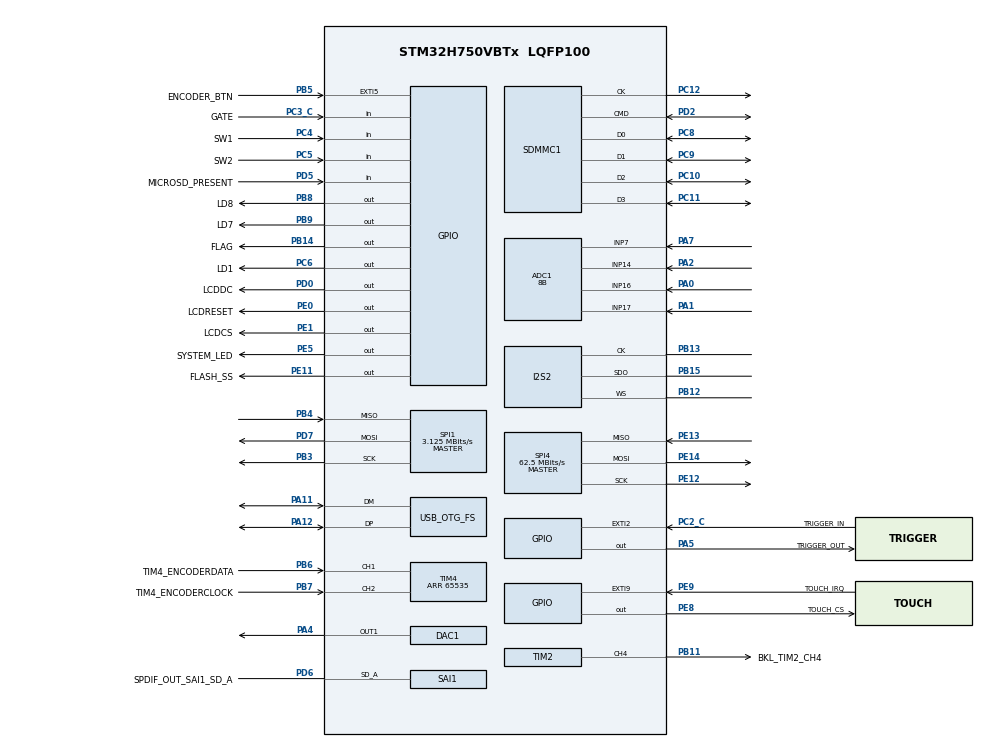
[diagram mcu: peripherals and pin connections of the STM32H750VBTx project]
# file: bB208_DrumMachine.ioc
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ADC1.Channel-0\#ChannelRegularConversion=ADC_CHANNEL_16
ADC1.Channel-1\#ChannelRegularConversion=ADC_CHANNEL_17
ADC1.Channel-2\#ChannelRegularConversion=ADC_CHANNEL_14
ADC1.Channel-3\#ChannelRegularConversion=ADC_CHANNEL_7
ADC1.ConversionDataManagement=ADC_CONVERSIONDATA_DMA_CIRCULAR
ADC1.EOCSelection=ADC_EOC_SEQ_CONV
ADC1.ExternalTrigConv=ADC_EXTERNALTRIG_T15_TRGO
ADC1.NbrOfConversion=4
ADC1.NbrOfConversionFlag=1
ADC1.OffsetNumber-0\#ChannelRegularConversion=ADC_OFFSET_NONE
ADC1.OffsetNumber-1\#ChannelRegularConversion=ADC_OFFSET_NONE
ADC1.OffsetNumber-2\#ChannelRegularConversion=ADC_OFFSET_NONE
ADC1.OffsetNumber-3\#ChannelRegularConversion=ADC_OFFSET_NONE
ADC1.OffsetSignedSaturation-0\#ChannelRegularConversion=DISABLE
ADC1.OffsetSignedSaturation-1\#ChannelRegularConversion=DISABLE
ADC1.OffsetSignedSaturation-2\#ChannelRegularConversion=DISABLE
ADC1.OffsetSignedSaturation-3\#ChannelRegularConversion=DISABLE
ADC1.OversamplingMode=ENABLE
ADC1.Rank-0\#ChannelRegularConversion=1
ADC1.Rank-1\#ChannelRegularConversion=2
ADC1.Rank-2\#ChannelRegularConversion=3
ADC1.Rank-3\#ChannelRegularConversion=4
ADC1.Ratio=8
ADC1.Resolution=ADC_RESOLUTION_8B
ADC1.RightBitShift=ADC_RIGHTBITSHIFT_3
ADC1.SamplingTime-0\#ChannelRegularConversion=ADC_SAMPLETIME_8CYCLES_5
ADC1.SamplingTime-1\#ChannelRegularConversion=ADC_SAMPLETIME_8CYCLES_5
ADC1.SamplingTime-2\#ChannelRegularConversion=ADC_SAMPLETIME_8CYCLES_5
ADC1.SamplingTime-3\#ChannelRegularConversion=ADC_SAMPLETIME_8CYCLES_5
ADC1.master=1
CORTEX_M7.AccessPermission-Cortex_Memory_Protection_Unit_Region0_Settings=MPU_REGION_FULL_ACCESS
CORTEX_M7.BaseAddress-Cortex_Memory_Protection_Unit_Region0_Settings=0x38000000
CORTEX_M7.CPU_DCache=Enabled
CORTEX_M7.CPU_ICache=Enabled
CORTEX_M7.DisableExec-Cortex_Memory_Protection_Unit_Region0_Settings=MPU_INSTRUCTION_ACCESS_ENABLE
CORTEX_M7.Enable-Cortex_Memory_Protection_Unit_Region0_Settings=MPU_REGION_ENABLE
CORTEX_M7.Enable-Cortex_Memory_Protection_Unit_Region1_Settings=__NULL
CORTEX_M7.Enable-Cortex_Memory_Protection_Unit_Region2_Settings=__NULL
CORTEX_M7.IsBufferable-Cortex_Memory_Protection_Unit_Region0_Settings=MPU_ACCESS_NOT_BUFFERABLE
CORTEX_M7.IsCacheable-Cortex_Memory_Protection_Unit_Region0_Settings=MPU_ACCESS_NOT_CACHEABLE
CORTEX_M7.IsShareable-Cortex_Memory_Protection_Unit_Region0_Settings=MPU_ACCESS_NOT_SHAREABLE
CORTEX_M7.MPU_Control=MPU_PRIVILEGED_DEFAULT
CORTEX_M7.Size-Cortex_Memory_Protection_Unit_Region0_Settings=MPU_REGION_SIZE_64KB
CORTEX_M7.TypeExtField-Cortex_Memory_Protection_Unit_Region0_Settings=MPU_TEX_LEVEL1
DAC1.DAC_Channel-DAC_OUT1_ExtAndInt=DAC_CHANNEL_1
DAC1.DAC_Trigger-DAC_OUT1_ExtAndInt=DAC_TRIGGER_T7_TRGO
Dma.ADC1.3.Direction=DMA_PERIPH_TO_MEMORY
Dma.ADC1.3.EventEnable=DISABLE
Dma.ADC1.3.FIFOMode=DMA_FIFOMODE_DISABLE
Dma.ADC1.3.Instance=DMA1_Stream4
Dma.ADC1.3.MemDataAlignment=DMA_MDATAALIGN_HALFWORD
Dma.ADC1.3.MemInc=DMA_MINC_ENABLE
Dma.ADC1.3.Mode=DMA_CIRCULAR
Dma.ADC1.3.PeriphDataAlignment=DMA_PDATAALIGN_HALFWORD
Dma.ADC1.3.PeriphInc=DMA_PINC_DISABLE
Dma.ADC1.3.Polarity=HAL_DMAMUX_REQ_GEN_RISING
Dma.ADC1.3.Priority=DMA_PRIORITY_LOW
Dma.ADC1.3.RequestNumber=1
Dma.ADC1.3.SignalID=NONE
Dma.ADC1.3.SyncEnable=DISABLE
Dma.ADC1.3.SyncPolarity=HAL_DMAMUX_SYNC_NO_EVENT
Dma.ADC1.3.SyncRequestNumber=1
Dma.ADC1.3.SyncSignalID=NONE
Dma.DAC1_CH1.0.Direction=DMA_MEMORY_TO_PERIPH
Dma.DAC1_CH1.0.EventEnable=DISABLE
Dma.DAC1_CH1.0.FIFOMode=DMA_FIFOMODE_DISABLE
Dma.DAC1_CH1.0.Instance=DMA1_Stream0
Dma.DAC1_CH1.0.MemDataAlignment=DMA_MDATAALIGN_HALFWORD
Dma.DAC1_CH1.0.MemInc=DMA_MINC_ENABLE
Dma.DAC1_CH1.0.Mode=DMA_CIRCULAR
Dma.DAC1_CH1.0.PeriphDataAlignment=DMA_PDATAALIGN_HALFWORD
Dma.DAC1_CH1.0.PeriphInc=DMA_PINC_DISABLE
Dma.DAC1_CH1.0.Polarity=HAL_DMAMUX_REQ_GEN_RISING
Dma.DAC1_CH1.0.Priority=DMA_PRIORITY_LOW
Dma.DAC1_CH1.0.RequestNumber=1
Dma.DAC1_CH1.0.SignalID=NONE
Dma.DAC1_CH1.0.SyncEnable=DISABLE
Dma.DAC1_CH1.0.SyncPolarity=HAL_DMAMUX_SYNC_NO_EVENT
Dma.DAC1_CH1.0.SyncRequestNumber=1
Dma.DAC1_CH1.0.SyncSignalID=NONE
Dma.Request0=DAC1_CH1
Dma.Request1=SAI1_A
Dma.Request2=SPI2_TX
Dma.Request3=ADC1
Dma.SAI1_A.1.Direction=DMA_MEMORY_TO_PERIPH
Dma.SAI1_A.1.EventEnable=DISABLE
Dma.SAI1_A.1.FIFOMode=DMA_FIFOMODE_DISABLE
Dma.SAI1_A.1.Instance=DMA1_Stream2
Dma.SAI1_A.1.MemDataAlignment=DMA_MDATAALIGN_HALFWORD
Dma.SAI1_A.1.MemInc=DMA_MINC_ENABLE
Dma.SAI1_A.1.Mode=DMA_CIRCULAR
Dma.SAI1_A.1.PeriphDataAlignment=DMA_PDATAALIGN_HALFWORD
Dma.SAI1_A.1.PeriphInc=DMA_PINC_DISABLE
Dma.SAI1_A.1.Polarity=HAL_DMAMUX_REQ_GEN_RISING
Dma.SAI1_A.1.Priority=DMA_PRIORITY_LOW
Dma.SAI1_A.1.RequestNumber=1
Dma.SAI1_A.1.SignalID=NONE
Dma.SAI1_A.1.SyncEnable=DISABLE
Dma.SAI1_A.1.SyncPolarity=HAL_DMAMUX_SYNC_NO_EVENT
Dma.SAI1_A.1.SyncRequestNumber=1
Dma.SAI1_A.1.SyncSignalID=NONE
Dma.SPI2_TX.2.Direction=DMA_MEMORY_TO_PERIPH
Dma.SPI2_TX.2.EventEnable=DISABLE
Dma.SPI2_TX.2.FIFOMode=DMA_FIFOMODE_DISABLE
Dma.SPI2_TX.2.Instance=DMA1_Stream3
Dma.SPI2_TX.2.MemDataAlignment=DMA_MDATAALIGN_WORD
Dma.SPI2_TX.2.MemInc=DMA_MINC_ENABLE
Dma.SPI2_TX.2.Mode=DMA_CIRCULAR
Dma.SPI2_TX.2.PeriphDataAlignment=DMA_PDATAALIGN_WORD
Dma.SPI2_TX.2.PeriphInc=DMA_PINC_DISABLE
Dma.SPI2_TX.2.Polarity=HAL_DMAMUX_REQ_GEN_RISING
Dma.SPI2_TX.2.Priority=DMA_PRIORITY_LOW
Dma.SPI2_TX.2.RequestNumber=1
Dma.SPI2_TX.2.SignalID=NONE
Dma.SPI2_TX.2.SyncEnable=DISABLE
Dma.SPI2_TX.2.SyncPolarity=HAL_DMAMUX_SYNC_NO_EVENT
Dma.SPI2_TX.2.SyncRequestNumber=1
Dma.SPI2_TX.2.SyncSignalID=NONE
FATFS.BSP.number=1
FATFS.USE_DMA_CODE_SD=0
FATFS._FS_LOCK=24
FATFS0.BSP.STBoard=false
FATFS0.BSP.api=Unknown
FATFS0.BSP.i2caddr=0
FATFS0.BSP.instance=PD5
FATFS0.BSP.ip=GPIO
FATFS0.BSP.mode=Input
FATFS0.BSP.name=Detect_SDIO
FATFS0.BSP.solution=PD5
I2S2.AudioFreq=I2S_AUDIOFREQ_48K
I2S2.Data24BitAlignment=I2S_DATA_24BIT_ALIGNMENT_RIGHT
I2S2.DataFormat=I2S_DATAFORMAT_16B
I2S2.ErrorAudioFreq=-1.35 %
I2S2.FullDuplexMode=I2S_MODE_SLAVE_FD
I2S2.Instance=SPI$Index
I2S2.RealAudioFreq=47.348 KHz
I2S2.VirtualMode=I2S_MODE_MASTER
Mcu.Family=STM32H7
Mcu.Name=STM32H750VBTx
Mcu.Package=LQFP100
NVIC.DMA1_Stream0_IRQn=true\:0\:0\:false\:false\:true\:false\:true
NVIC.DMA1_Stream2_IRQn=true\:0\:0\:false\:false\:true\:false\:true
NVIC.DMA1_Stream3_IRQn=true\:0\:0\:false\:false\:true\:false\:true
NVIC.DMA1_Stream4_IRQn=true\:0\:0\:false\:false\:true\:false\:true
NVIC.EXTI2_IRQn=true\:0\:0\:false\:false\:true\:true\:true
NVIC.EXTI9_5_IRQn=true\:0\:0\:true\:false\:true\:true\:true
NVIC.HSEM1_IRQn=true\:0\:0\:false\:false\:true\:true\:true
NVIC.OTG_FS_IRQn=true\:0\:0\:false\:false\:true\:false\:true
NVIC.PriorityGroup=NVIC_PRIORITYGROUP_4
NVIC.TIM15_IRQn=true\:0\:0\:false\:false\:true\:true\:true
NVIC.TIM17_IRQn=true\:1\:0\:true\:false\:true\:true\:true
NVIC.TIM4_IRQn=true\:0\:0\:true\:false\:true\:true\:true
NVIC.TIM5_IRQn=true\:0\:0\:true\:false\:true\:true\:true
NVIC.TIM7_IRQn=true\:0\:0\:true\:false\:true\:true\:true
NVIC.TIM8_TRG_COM_TIM14_IRQn=true\:0\:0\:true\:false\:true\:true\:true
PA0.Mode=IN16-Single-Ended
PA0.Signal=ADC1_INP16
PA1.Mode=IN17-Single-Ended
PA1.Signal=ADC1_INP17
PA11.Mode=Device_Only
PA11.Signal=USB_OTG_FS_DM
PA12.Mode=Device_Only
PA12.Signal=USB_OTG_FS_DP
PA13\ (JTMS/SWDIO).Mode=Serial_Wire
PA13\ (JTMS/SWDIO).Signal=DEBUG_JTMS-SWDIO
PA14\ (JTCK/SWCLK).Mode=Serial_Wire
PA14\ (JTCK/SWCLK).Signal=DEBUG_JTCK-SWCLK
PA2.Signal=ADCx_INP14
PA4.Signal=COMP_DAC11_group
PA5.GPIO_Label=TRIGGER_OUT
PA5.Signal=GPIO_Output
PA7.Signal=ADCx_INP7
PB11.GPIO_Label=BKL_TIM2_CH4
PB11.GPIO_PuPd=GPIO_PULLDOWN
PB11.Signal=S_TIM2_CH4
PB12.Mode=Half_Duplex_Master_Tx
PB12.Signal=I2S2_WS
PB13.Mode=Half_Duplex_Master_Tx
PB13.Signal=I2S2_CK
PB14.GPIO_Label=FLAG
PB14.GPIO_Speed=GPIO_SPEED_FREQ_VERY_HIGH
PB14.Signal=GPIO_Output
PB15.Mode=Half_Duplex_Master_Tx
PB15.Signal=I2S2_SDO
PB3\ (JTDO/TRACESWO).GPIO_Speed=GPIO_SPEED_FREQ_HIGH
PB3\ (JTDO/TRACESWO).Mode=Full_Duplex_Master
PB3\ (JTDO/TRACESWO).Signal=SPI1_SCK
PB4\ (NJTRST).GPIO_PuPd=GPIO_PULLUP
PB4\ (NJTRST).GPIO_Speed=GPIO_SPEED_FREQ_HIGH
PB4\ (NJTRST).Mode=Full_Duplex_Master
PB4\ (NJTRST).Signal=SPI1_MISO
PB5.GPIO_Label=ENCODER_BTN
PB5.GPIO_ModeDefaultEXTI=GPIO_MODE_IT_FALLING
PB5.GPIO_PuPd=GPIO_PULLUP
PB5.Signal=GPXTI5
PB6.GPIO_Label=TIM4_ENCODERDATA
PB6.GPIO_PuPd=GPIO_PULLUP
PB6.Signal=S_TIM4_CH1
PB7.GPIO_Label=TIM4_ENCODERCLOCK
PB7.GPIO_PuPd=GPIO_PULLUP
PB7.Signal=S_TIM4_CH2
PB8.GPIO_Label=LD8
PB8.Signal=GPIO_Output
PB9.GPIO_Label=LD7
PB9.Signal=GPIO_Output
PC10.GPIO_Speed_High_Default=GPIO_SPEED_FREQ_VERY_HIGH
PC10.Mode=SD_4_bits_Wide_bus
PC10.Signal=SDMMC1_D2
PC11.GPIO_Speed_High_Default=GPIO_SPEED_FREQ_VERY_HIGH
PC11.Mode=SD_4_bits_Wide_bus
PC11.Signal=SDMMC1_D3
PC12.GPIO_PuPd=GPIO_PULLUP
PC12.Mode=SD_4_bits_Wide_bus
PC12.Signal=SDMMC1_CK
PC2_C.GPIO_Label=TRIGGER_IN
PC2_C.GPIO_ModeDefaultEXTI=GPIO_MODE_IT_RISING_FALLING
PC2_C.GPIO_PuPd=GPIO_PULLUP
PC2_C.Signal=GPXTI2
PC3_C.GPIO_Label=GATE
PC3_C.Signal=GPIO_Input
PC4.GPIO_Label=SW1
PC4.GPIO_PuPd=GPIO_PULLUP
PC4.Signal=GPIO_Input
PC5.GPIO_Label=SW2
PC5.GPIO_PuPd=GPIO_PULLUP
PC5.Signal=GPIO_Input
PC6.GPIO_Label=LD1
PC6.Signal=GPIO_Output
PC8.GPIO_PuPd=GPIO_PULLUP
PC8.GPIO_Speed_High_Default=GPIO_SPEED_FREQ_VERY_HIGH
PC8.Mode=SD_4_bits_Wide_bus
PC8.Signal=SDMMC1_D0
PC9.GPIO_Speed_High_Default=GPIO_SPEED_FREQ_VERY_HIGH
PC9.Mode=SD_4_bits_Wide_bus
PC9.Signal=SDMMC1_D1
PD0.GPIO_Label=LCDDC
PD0.GPIO_PuPd=GPIO_PULLUP
PD0.GPIO_Speed=GPIO_SPEED_FREQ_VERY_HIGH
PD0.Signal=GPIO_Output
PD2.GPIO_PuPd=GPIO_PULLUP
PD2.GPIO_Speed_High_Default=GPIO_SPEED_FREQ_VERY_HIGH
PD2.Mode=SD_4_bits_Wide_bus
PD2.Signal=SDMMC1_CMD
PD5.GPIO_Label=MICROSD_PRESENT
PD5.GPIO_PuPd=GPIO_PULLUP
PD5.Signal=GPIO_Input
PD6.GPIO_Label=SPDIF_OUT_SAI1_SD_A
PD6.Mode=SAI_A_SPDIF
PD6.Signal=SAI1_SD_A
PD7.GPIO_Speed=GPIO_SPEED_FREQ_HIGH
PD7.Mode=Full_Duplex_Master
PD7.Signal=SPI1_MOSI
PE0.GPIO_Label=LCDRESET
PE0.GPIO_PuPd=GPIO_PULLUP
PE0.GPIO_Speed=GPIO_SPEED_FREQ_VERY_HIGH
PE0.Signal=GPIO_Output
PE1.GPIO_Label=LCDCS
PE1.GPIO_PuPd=GPIO_PULLUP
PE1.GPIO_Speed=GPIO_SPEED_FREQ_VERY_HIGH
PE1.PinState=GPIO_PIN_SET
PE1.Signal=GPIO_Output
PE11.GPIO_Label=FLASH_SS
PE11.GPIO_PuPd=GPIO_PULLUP
PE11.GPIO_Speed=GPIO_SPEED_FREQ_HIGH
PE11.PinState=GPIO_PIN_SET
PE11.Signal=GPIO_Output
PE12.GPIO_Speed=GPIO_SPEED_FREQ_HIGH
PE12.Mode=Full_Duplex_Master
PE12.Signal=SPI4_SCK
PE13.GPIO_PuPd=GPIO_PULLUP
PE13.GPIO_Speed=GPIO_SPEED_FREQ_HIGH
PE13.Mode=Full_Duplex_Master
PE13.Signal=SPI4_MISO
PE14.GPIO_Speed=GPIO_SPEED_FREQ_HIGH
PE14.Mode=Full_Duplex_Master
PE14.Signal=SPI4_MOSI
PE5.GPIO_Label=SYSTEM_LED
PE5.Signal=GPIO_Output
PE8.GPIO_Label=TOUCH_CS
PE8.GPIO_PuPd=GPIO_PULLUP
PE8.GPIO_Speed=GPIO_SPEED_FREQ_VERY_HIGH
PE8.PinState=GPIO_PIN_SET
PE8.Signal=GPIO_Output
PE9.GPIO_Label=TOUCH_IRQ
PE9.GPIO_ModeDefaultEXTI=GPIO_MODE_IT_FALLING
PE9.GPIO_PuPd=GPIO_PULLUP
PE9.Signal=GPXTI9
PH0-OSC_IN\ (PH0).Mode=HSE-External-Oscillator
PH0-OSC_IN\ (PH0).Signal=RCC_OSC_IN
PH1-OSC_OUT\ (PH1).Mode=HSE-External-Oscillator
PH1-OSC_OUT\ (PH1).Signal=RCC_OSC_OUT
ProjectManager.HeapSize=0x200
ProjectManager.StackSize=0x400
ProjectManager.TargetToolchain=STM32CubeIDE
RCC.ADCCLockSelection=RCC_ADCCLKSOURCE_PLL3
RCC.ADCFreq_Value=12500000
RCC.APB1Freq_Value=120000000
RCC.APB2Freq_Value=60000000
RCC.APB3Freq_Value=120000000
RCC.APB4Freq_Value=120000000
RCC.CortexFreq_Value=60000000
RCC.Cortex_Div=SYSTICK_CLKSOURCE_HCLK_DIV8
RCC.D1PPRE=RCC_APB3_DIV2
RCC.D2PPRE1=RCC_APB1_DIV2
RCC.D2PPRE2=RCC_APB2_DIV4
RCC.D3PPRE=RCC_APB4_DIV2
RCC.DIVM1=2
RCC.DIVM2=15
RCC.DIVM3=24
RCC.DIVN1=80
RCC.DIVN2=192
RCC.DIVN3=250
RCC.DIVP2=25
RCC.DIVP3=5
RCC.DIVQ1=20
RCC.DIVQ2=3
RCC.DIVR1=8
RCC.DIVR3=20
RCC.HCLKFreq_Value=240000000
RCC.HPRE=RCC_HCLK_DIV2
RCC.HSE_VALUE=24000000
RCC.I2C123CLockSelection=RCC_I2C123CLKSOURCE_CSI
RCC.PLLFRACN=0
RCC.PLLSourceVirtual=RCC_PLLSOURCE_HSE
RCC.SAI1CLockSelection=RCC_SAI1CLKSOURCE_PLL2
RCC.SPI123CLockSelection=RCC_SPI123CLKSOURCE_PLL3
RCC.SYSCLKFreq_VALUE=480000000
RCC.SYSCLKSource=RCC_SYSCLKSOURCE_PLLCLK
RCC.Spi45ClockSelection=RCC_SPI45CLKSOURCE_PLL3
RCC.USBCLockSelection=RCC_USBCLKSOURCE_HSI48
RCC.USBFreq_Value=48000000
SAI1.AudioFrequency-SAI_A_SPDIF=SAI_AUDIO_FREQUENCY_48K
SAI1.FIFOThreshold-SAI_A_SPDIF=SAI_FIFOTHRESHOLD_HF
SAI1.Instance-SAI_A_SPDIF=SAI$Index_Block_A
SAI1.MonoStereoMode-SAI_A_SPDIF=SAI_MONOMODE
SAI1.OutputDrive-SAI_A_SPDIF=SAI_OUTPUTDRIVE_ENABLE
SAI1.RealAudioFreq-SAI_A_SPDIF=192.0 KHz
SAI1.VirtualMode-SAI_A_SPDIF=VM_SPDIF
SDMMC1.ClockDiv=4
SDMMC1.HardwareFlowControl=SDMMC_HARDWARE_FLOW_CONTROL_DISABLE
SDMMC1.TransceiverPresent=SDMMC_TRANSCEIVER_NOT_PRESENT
SH.ADCx_INP14.0=ADC1_INP14,IN14-Single-Ended
SH.ADCx_INP7.0=ADC1_INP7,IN7-Single-Ended
SH.COMP_DAC11_group.0=DAC1_OUT1,DAC_OUT1_ExtAndInt
SH.S_TIM2_CH4.0=TIM2_CH4,PWM Generation4 CH4
SH.S_TIM4_CH1.0=TIM4_CH1,Encoder_Interface
SH.S_TIM4_CH2.0=TIM4_CH2,Encoder_Interface
SPI1.BaudRatePrescaler=SPI_BAUDRATEPRESCALER_16
SPI1.CalculateBaudRate=3.125 MBits/s
SPI1.DataSize=SPI_DATASIZE_8BIT
SPI1.Direction=SPI_DIRECTION_2LINES
SPI1.FifoThreshold=SPI_FIFO_THRESHOLD_04DATA
SPI1.Mode=SPI_MODE_MASTER
SPI1.VirtualType=VM_MASTER
SPI4.BaudRatePrescaler=SPI_BAUDRATEPRESCALER_2
SPI4.CalculateBaudRate=62.5 MBits/s
SPI4.DataSize=SPI_DATASIZE_8BIT
SPI4.Direction=SPI_DIRECTION_2LINES
SPI4.FifoThreshold=SPI_FIFO_THRESHOLD_01DATA
SPI4.Mode=SPI_MODE_MASTER
SPI4.VirtualType=VM_MASTER
TIM13.ClockDivision=TIM_CLOCKDIVISION_DIV4
TIM13.Prescaler=60000
TIM14.Period=1999
TIM14.Prescaler=1199
TIM15.Period=10000
TIM15.Prescaler=240
TIM15.TIM_MasterOutputTrigger=TIM_TRGO_UPDATE
TIM16.Prescaler=120
TIM17.Period=9999
TIM17.Prescaler=1199
TIM2.Channel-PWM\ Generation4\ CH4=TIM_CHANNEL_4
TIM2.OCPolarity_4=TIM_OCPOLARITY_HIGH
TIM2.Period=1000
TIM2.Prescaler=240
TIM2.Pulse-PWM\ Generation4\ CH4=900
TIM4.EncoderMode=TIM_ENCODERMODE_TI12
TIM4.IC1Filter=15
TIM4.IC1Prescaler=TIM_ICPSC_DIV2
TIM4.IC2Filter=15
TIM4.IC2Polarity=TIM_ICPOLARITY_RISING
TIM4.IC2Prescaler=TIM_ICPSC_DIV2
TIM4.Period=65535
TIM5.Period=7199999
TIM5.Prescaler=1999
TIM7.Period=1811
TIM7.Prescaler=2
TIM7.TIM_MasterOutputTrigger=TIM_TRGO_UPDATE
USB_DEVICE.CLASS_NAME_FS=CDC
USB_DEVICE.VirtualMode-CDC_FS=Cdc
USB_DEVICE.VirtualModeFS=Cdc_FS
USB_OTG_FS.VirtualMode=Device_Only
VP_FATFS_VS_SDIO.Mode=SDIO
VP_TIM13_VS_ClockSourceINT.Mode=Enable_Timer
VP_TIM14_VS_ClockSourceINT.Mode=Enable_Timer
VP_TIM15_VS_ClockSourceINT.Mode=Internal
VP_TIM16_VS_ClockSourceINT.Mode=Enable_Timer
VP_TIM17_VS_ClockSourceINT.Mode=Enable_Timer
VP_TIM5_VS_ClockSourceINT.Mode=Internal
VP_TIM7_VS_ClockSourceINT.Mode=Enable_Timer
VP_USB_DEVICE_VS_USB_DEVICE_CDC_FS.Mode=CDC_FS
board=custom

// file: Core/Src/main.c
/* USER CODE BEGIN Header */
/**
  ******************************************************************************
  * @file           : main.c
  * @brief          : Main program body
  ******************************************************************************
  * @attention
  *
  * Copyright (c) 2022 STMicroelectronics.
  * All rights reserved.
  *
  * This software is licensed under terms that can be found in the LICENSE file
  * in the root directory of this software component.
  * If no LICENSE file comes with this software, it is provided AS-IS.
  *
  ******************************************************************************
  */
/* USER CODE END Header */
#include "main.h"
#include "fatfs.h"
#include "usb_device.h"

ADC_HandleTypeDef hadc1;
DMA_HandleTypeDef hdma_adc1;

DAC_HandleTypeDef hdac1;
DMA_HandleTypeDef hdma_dac1_ch1;

I2S_HandleTypeDef hi2s2;
DMA_HandleTypeDef hdma_spi2_tx;

SAI_HandleTypeDef hsai_BlockA1;
DMA_HandleTypeDef hdma_sai1_a;

SD_HandleTypeDef hsd1;

SPI_HandleTypeDef hspi1;
SPI_HandleTypeDef hspi4;

TIM_HandleTypeDef htim2;
TIM_HandleTypeDef htim4;
TIM_HandleTypeDef htim5;
TIM_HandleTypeDef htim7;
TIM_HandleTypeDef htim13;
TIM_HandleTypeDef htim14;
TIM_HandleTypeDef htim15;
TIM_HandleTypeDef htim16;
TIM_HandleTypeDef htim17;

void SystemClock_Config(void);
void PeriphCommonClock_Config(void);
static void MPU_Config(void);
static void MX_GPIO_Init(void);
static void MX_DMA_Init(void);
static void MX_SPI4_Init(void);
static void MX_SDMMC1_SD_Init(void);
static void MX_TIM2_Init(void);
static void MX_TIM17_Init(void);
static void MX_ADC1_Init(void);
static void MX_DAC1_Init(void);
static void MX_I2S2_Init(void);
static void MX_SPI1_Init(void);
static void MX_TIM4_Init(void);
static void MX_SAI1_Init(void);
static void MX_TIM7_Init(void);
static void MX_TIM15_Init(void);
static void MX_TIM16_Init(void);
static void MX_TIM14_Init(void);
static void MX_TIM5_Init(void);
static void MX_TIM13_Init(void);

int main(void)
{

  /* MPU Configuration--------------------------------------------------------*/
  MPU_Config();

  /* Enable I-Cache---------------------------------------------------------*/
  SCB_EnableICache();

  /* Enable D-Cache---------------------------------------------------------*/
  SCB_EnableDCache();

  /* MCU Configuration--------------------------------------------------------*/

  /* Reset of all peripherals, Initializes the Flash interface and the Systick. */
  HAL_Init();

  /* Configure the system clock */
  SystemClock_Config();

/* Configure the peripherals common clocks */
  PeriphCommonClock_Config();

  /* Initialize all configured peripherals */
  MX_GPIO_Init();
  MX_DMA_Init();
  MX_SPI4_Init();
  MX_SDMMC1_SD_Init();
  MX_TIM2_Init();
  MX_TIM17_Init();
  MX_ADC1_Init();
  MX_DAC1_Init();
  MX_I2S2_Init();
  MX_SPI1_Init();
  MX_TIM4_Init();
  MX_SAI1_Init();
  MX_TIM7_Init();
  MX_TIM15_Init();
  MX_FATFS_Init();
  MX_TIM16_Init();
  MX_TIM14_Init();
  MX_TIM5_Init();
  MX_TIM13_Init();
  MX_USB_DEVICE_Init();
  /* USER CODE BEGIN 2 */
  bB2xx_Init();

  /* USER CODE END 2 */

  /* Infinite loop */
  /* USER CODE BEGIN WHILE */
  while (1)
  {
	  bB2xx_Loop();

    /* USER CODE END WHILE */

  }
}

void SystemClock_Config(void)
{
  RCC_OscInitTypeDef RCC_OscInitStruct = {0};
  RCC_ClkInitTypeDef RCC_ClkInitStruct = {0};

  /** Supply configuration update enable
  */
  HAL_PWREx_ConfigSupply(PWR_LDO_SUPPLY);
  /** Configure the main internal regulator output voltage
  */
  __HAL_PWR_VOLTAGESCALING_CONFIG(PWR_REGULATOR_VOLTAGE_SCALE0);

  while(!__HAL_PWR_GET_FLAG(PWR_FLAG_VOSRDY)) {}
  /** Macro to configure the PLL clock source
  */
  __HAL_RCC_PLL_PLLSOURCE_CONFIG(RCC_PLLSOURCE_HSE);
  /** Initializes the RCC Oscillators according to the specified parameters
  * in the RCC_OscInitTypeDef structure.
  */
  RCC_OscInitStruct.OscillatorType = RCC_OSCILLATORTYPE_HSI48|RCC_OSCILLATORTYPE_HSE;
  RCC_OscInitStruct.HSEState = RCC_HSE_ON;
  RCC_OscInitStruct.HSI48State = RCC_HSI48_ON;
  RCC_OscInitStruct.PLL.PLLState = RCC_PLL_ON;
  RCC_OscInitStruct.PLL.PLLSource = RCC_PLLSOURCE_HSE;
  RCC_OscInitStruct.PLL.PLLM = 2;
  RCC_OscInitStruct.PLL.PLLN = 80;
  RCC_OscInitStruct.PLL.PLLP = 2;
  RCC_OscInitStruct.PLL.PLLQ = 20;
  RCC_OscInitStruct.PLL.PLLR = 8;
  RCC_OscInitStruct.PLL.PLLRGE = RCC_PLL1VCIRANGE_3;
  RCC_OscInitStruct.PLL.PLLVCOSEL = RCC_PLL1VCOWIDE;
  RCC_OscInitStruct.PLL.PLLFRACN = 0;
  if (HAL_RCC_OscConfig(&RCC_OscInitStruct) != HAL_OK)
  {
    Error_Handler();
  }
  /** Initializes the CPU, AHB and APB buses clocks
  */
  RCC_ClkInitStruct.ClockType = RCC_CLOCKTYPE_HCLK|RCC_CLOCKTYPE_SYSCLK
                              |RCC_CLOCKTYPE_PCLK1|RCC_CLOCKTYPE_PCLK2
                              |RCC_CLOCKTYPE_D3PCLK1|RCC_CLOCKTYPE_D1PCLK1;
  RCC_ClkInitStruct.SYSCLKSource = RCC_SYSCLKSOURCE_PLLCLK;
  RCC_ClkInitStruct.SYSCLKDivider = RCC_SYSCLK_DIV1;
  RCC_ClkInitStruct.AHBCLKDivider = RCC_HCLK_DIV2;
  RCC_ClkInitStruct.APB3CLKDivider = RCC_APB3_DIV2;
  RCC_ClkInitStruct.APB1CLKDivider = RCC_APB1_DIV2;
  RCC_ClkInitStruct.APB2CLKDivider = RCC_APB2_DIV4;
  RCC_ClkInitStruct.APB4CLKDivider = RCC_APB4_DIV2;

  if (HAL_RCC_ClockConfig(&RCC_ClkInitStruct, FLASH_LATENCY_4) != HAL_OK)
  {
    Error_Handler();
  }
}

void PeriphCommonClock_Config(void)
{
  RCC_PeriphCLKInitTypeDef PeriphClkInitStruct = {0};

  /** Initializes the peripherals clock
  */
  PeriphClkInitStruct.PeriphClockSelection = RCC_PERIPHCLK_ADC|RCC_PERIPHCLK_SPI2
                              |RCC_PERIPHCLK_SPI1|RCC_PERIPHCLK_SPI4;
  PeriphClkInitStruct.PLL3.PLL3M = 24;
  PeriphClkInitStruct.PLL3.PLL3N = 250;
  PeriphClkInitStruct.PLL3.PLL3P = 5;
  PeriphClkInitStruct.PLL3.PLL3Q = 2;
  PeriphClkInitStruct.PLL3.PLL3R = 20;
  PeriphClkInitStruct.PLL3.PLL3RGE = RCC_PLL3VCIRANGE_0;
  PeriphClkInitStruct.PLL3.PLL3VCOSEL = RCC_PLL3VCOWIDE;
  PeriphClkInitStruct.PLL3.PLL3FRACN = 0;
  PeriphClkInitStruct.Spi123ClockSelection = RCC_SPI123CLKSOURCE_PLL3;
  PeriphClkInitStruct.Spi45ClockSelection = RCC_SPI45CLKSOURCE_PLL3;
  PeriphClkInitStruct.AdcClockSelection = RCC_ADCCLKSOURCE_PLL3;
  if (HAL_RCCEx_PeriphCLKConfig(&PeriphClkInitStruct) != HAL_OK)
  {
    Error_Handler();
  }
}

static void MX_ADC1_Init(void)
{

  ADC_MultiModeTypeDef multimode = {0};
  ADC_ChannelConfTypeDef sConfig = {0};

  /** Common config
  */
  hadc1.Instance = ADC1;
  hadc1.Init.ClockPrescaler = ADC_CLOCK_ASYNC_DIV1;
  hadc1.Init.Resolution = ADC_RESOLUTION_8B;
  hadc1.Init.ScanConvMode = ADC_SCAN_ENABLE;
  hadc1.Init.EOCSelection = ADC_EOC_SEQ_CONV;
  hadc1.Init.LowPowerAutoWait = DISABLE;
  hadc1.Init.ContinuousConvMode = DISABLE;
  hadc1.Init.NbrOfConversion = 4;
  hadc1.Init.DiscontinuousConvMode = DISABLE;
  hadc1.Init.ExternalTrigConv = ADC_EXTERNALTRIG_T15_TRGO;
  hadc1.Init.ExternalTrigConvEdge = ADC_EXTERNALTRIGCONVEDGE_RISING;
  hadc1.Init.ConversionDataManagement = ADC_CONVERSIONDATA_DMA_CIRCULAR;
  hadc1.Init.Overrun = ADC_OVR_DATA_PRESERVED;
  hadc1.Init.LeftBitShift = ADC_LEFTBITSHIFT_NONE;
  hadc1.Init.OversamplingMode = ENABLE;
  hadc1.Init.Oversampling.Ratio = 8;
  hadc1.Init.Oversampling.RightBitShift = ADC_RIGHTBITSHIFT_3;
  hadc1.Init.Oversampling.TriggeredMode = ADC_TRIGGEREDMODE_SINGLE_TRIGGER;
  hadc1.Init.Oversampling.OversamplingStopReset = ADC_REGOVERSAMPLING_CONTINUED_MODE;
  if (HAL_ADC_Init(&hadc1) != HAL_OK)
  {
    Error_Handler();
  }
  /** Configure the ADC multi-mode
  */
  multimode.Mode = ADC_MODE_INDEPENDENT;
  if (HAL_ADCEx_MultiModeConfigChannel(&hadc1, &multimode) != HAL_OK)
  {
    Error_Handler();
  }
  /** Configure Regular Channel
  */
  sConfig.Channel = ADC_CHANNEL_16;
  sConfig.Rank = ADC_REGULAR_RANK_1;
  sConfig.SamplingTime = ADC_SAMPLETIME_8CYCLES_5;
  sConfig.SingleDiff = ADC_SINGLE_ENDED;
  sConfig.OffsetNumber = ADC_OFFSET_NONE;
  sConfig.Offset = 0;
  sConfig.OffsetSignedSaturation = DISABLE;
  if (HAL_ADC_ConfigChannel(&hadc1, &sConfig) != HAL_OK)
  {
    Error_Handler();
  }
  /** Configure Regular Channel
  */
  sConfig.Channel = ADC_CHANNEL_17;
  sConfig.Rank = ADC_REGULAR_RANK_2;
  if (HAL_ADC_ConfigChannel(&hadc1, &sConfig) != HAL_OK)
  {
    Error_Handler();
  }
  /** Configure Regular Channel
  */
  sConfig.Channel = ADC_CHANNEL_14;
  sConfig.Rank = ADC_REGULAR_RANK_3;
  if (HAL_ADC_ConfigChannel(&hadc1, &sConfig) != HAL_OK)
  {
    Error_Handler();
  }
  /** Configure Regular Channel
  */
  sConfig.Channel = ADC_CHANNEL_7;
  sConfig.Rank = ADC_REGULAR_RANK_4;
  if (HAL_ADC_ConfigChannel(&hadc1, &sConfig) != HAL_OK)
  {
    Error_Handler();
  }

}

static void MX_DAC1_Init(void)
{

  DAC_ChannelConfTypeDef sConfig = {0};

  /** DAC Initialization
  */
  hdac1.Instance = DAC1;
  if (HAL_DAC_Init(&hdac1) != HAL_OK)
  {
    Error_Handler();
  }
  /** DAC channel OUT1 config
  */
  sConfig.DAC_SampleAndHold = DAC_SAMPLEANDHOLD_DISABLE;
  sConfig.DAC_Trigger = DAC_TRIGGER_T7_TRGO;
  sConfig.DAC_OutputBuffer = DAC_OUTPUTBUFFER_ENABLE;
  sConfig.DAC_ConnectOnChipPeripheral = DAC_CHIPCONNECT_ENABLE;
  sConfig.DAC_UserTrimming = DAC_TRIMMING_FACTORY;
  if (HAL_DAC_ConfigChannel(&hdac1, &sConfig, DAC_CHANNEL_1) != HAL_OK)
  {
    Error_Handler();
  }

}

static void MX_I2S2_Init(void)
{

  hi2s2.Instance = SPI2;
  hi2s2.Init.Mode = I2S_MODE_MASTER_TX;
  hi2s2.Init.Standard = I2S_STANDARD_PHILIPS;
  hi2s2.Init.DataFormat = I2S_DATAFORMAT_16B;
  hi2s2.Init.MCLKOutput = I2S_MCLKOUTPUT_DISABLE;
  hi2s2.Init.AudioFreq = I2S_AUDIOFREQ_48K;
  hi2s2.Init.CPOL = I2S_CPOL_LOW;
  hi2s2.Init.FirstBit = I2S_FIRSTBIT_MSB;
  hi2s2.Init.WSInversion = I2S_WS_INVERSION_DISABLE;
  hi2s2.Init.Data24BitAlignment = I2S_DATA_24BIT_ALIGNMENT_RIGHT;
  hi2s2.Init.MasterKeepIOState = I2S_MASTER_KEEP_IO_STATE_DISABLE;
  if (HAL_I2S_Init(&hi2s2) != HAL_OK)
  {
    Error_Handler();
  }

}

static void MX_SAI1_Init(void)
{

  hsai_BlockA1.Instance = SAI1_Block_A;
  hsai_BlockA1.Init.Protocol = SAI_SPDIF_PROTOCOL;
  hsai_BlockA1.Init.AudioMode = SAI_MODEMASTER_TX;
  hsai_BlockA1.Init.Synchro = SAI_ASYNCHRONOUS;
  hsai_BlockA1.Init.OutputDrive = SAI_OUTPUTDRIVE_ENABLE;
  hsai_BlockA1.Init.FIFOThreshold = SAI_FIFOTHRESHOLD_HF;
  hsai_BlockA1.Init.AudioFrequency = SAI_AUDIO_FREQUENCY_48K;
  hsai_BlockA1.Init.MonoStereoMode = SAI_MONOMODE;
  hsai_BlockA1.Init.CompandingMode = SAI_NOCOMPANDING;
  hsai_BlockA1.Init.PdmInit.Activation = DISABLE;
  hsai_BlockA1.Init.PdmInit.MicPairsNbr = 1;
  hsai_BlockA1.Init.PdmInit.ClockEnable = SAI_PDM_CLOCK1_ENABLE;
  if (HAL_SAI_Init(&hsai_BlockA1) != HAL_OK)
  {
    Error_Handler();
  }

}

static void MX_SDMMC1_SD_Init(void)
{

  hsd1.Instance = SDMMC1;
  hsd1.Init.ClockEdge = SDMMC_CLOCK_EDGE_RISING;
  hsd1.Init.ClockPowerSave = SDMMC_CLOCK_POWER_SAVE_DISABLE;
  hsd1.Init.BusWide = SDMMC_BUS_WIDE_4B;
  hsd1.Init.HardwareFlowControl = SDMMC_HARDWARE_FLOW_CONTROL_DISABLE;
  hsd1.Init.ClockDiv = 4;

}

static void MX_SPI1_Init(void)
{

  /* SPI1 parameter configuration*/
  hspi1.Instance = SPI1;
  hspi1.Init.Mode = SPI_MODE_MASTER;
  hspi1.Init.Direction = SPI_DIRECTION_2LINES;
  hspi1.Init.DataSize = SPI_DATASIZE_8BIT;
  hspi1.Init.CLKPolarity = SPI_POLARITY_LOW;
  hspi1.Init.CLKPhase = SPI_PHASE_1EDGE;
  hspi1.Init.NSS = SPI_NSS_SOFT;
  hspi1.Init.BaudRatePrescaler = SPI_BAUDRATEPRESCALER_16;
  hspi1.Init.FirstBit = SPI_FIRSTBIT_MSB;
  hspi1.Init.TIMode = SPI_TIMODE_DISABLE;
  hspi1.Init.CRCCalculation = SPI_CRCCALCULATION_DISABLE;
  hspi1.Init.CRCPolynomial = 0x0;
  hspi1.Init.NSSPMode = SPI_NSS_PULSE_ENABLE;
  hspi1.Init.NSSPolarity = SPI_NSS_POLARITY_LOW;
  hspi1.Init.FifoThreshold = SPI_FIFO_THRESHOLD_04DATA;
  hspi1.Init.TxCRCInitializationPattern = SPI_CRC_INITIALIZATION_ALL_ZERO_PATTERN;
  hspi1.Init.RxCRCInitializationPattern = SPI_CRC_INITIALIZATION_ALL_ZERO_PATTERN;
  hspi1.Init.MasterSSIdleness = SPI_MASTER_SS_IDLENESS_00CYCLE;
  hspi1.Init.MasterInterDataIdleness = SPI_MASTER_INTERDATA_IDLENESS_00CYCLE;
  hspi1.Init.MasterReceiverAutoSusp = SPI_MASTER_RX_AUTOSUSP_DISABLE;
  hspi1.Init.MasterKeepIOState = SPI_MASTER_KEEP_IO_STATE_DISABLE;
  hspi1.Init.IOSwap = SPI_IO_SWAP_DISABLE;
  if (HAL_SPI_Init(&hspi1) != HAL_OK)
  {
    Error_Handler();
  }

}

static void MX_SPI4_Init(void)
{

  /* SPI4 parameter configuration*/
  hspi4.Instance = SPI4;
  hspi4.Init.Mode = SPI_MODE_MASTER;
  hspi4.Init.Direction = SPI_DIRECTION_2LINES;
  hspi4.Init.DataSize = SPI_DATASIZE_8BIT;
  hspi4.Init.CLKPolarity = SPI_POLARITY_LOW;
  hspi4.Init.CLKPhase = SPI_PHASE_1EDGE;
  hspi4.Init.NSS = SPI_NSS_SOFT;
  hspi4.Init.BaudRatePrescaler = SPI_BAUDRATEPRESCALER_2;
  hspi4.Init.FirstBit = SPI_FIRSTBIT_MSB;
  hspi4.Init.TIMode = SPI_TIMODE_DISABLE;
  hspi4.Init.CRCCalculation = SPI_CRCCALCULATION_DISABLE;
  hspi4.Init.CRCPolynomial = 0x0;
  hspi4.Init.NSSPMode = SPI_NSS_PULSE_ENABLE;
  hspi4.Init.NSSPolarity = SPI_NSS_POLARITY_LOW;
  hspi4.Init.FifoThreshold = SPI_FIFO_THRESHOLD_01DATA;
  hspi4.Init.TxCRCInitializationPattern = SPI_CRC_INITIALIZATION_ALL_ZERO_PATTERN;
  hspi4.Init.RxCRCInitializationPattern = SPI_CRC_INITIALIZATION_ALL_ZERO_PATTERN;
  hspi4.Init.MasterSSIdleness = SPI_MASTER_SS_IDLENESS_00CYCLE;
  hspi4.Init.MasterInterDataIdleness = SPI_MASTER_INTERDATA_IDLENESS_00CYCLE;
  hspi4.Init.MasterReceiverAutoSusp = SPI_MASTER_RX_AUTOSUSP_DISABLE;
  hspi4.Init.MasterKeepIOState = SPI_MASTER_KEEP_IO_STATE_DISABLE;
  hspi4.Init.IOSwap = SPI_IO_SWAP_DISABLE;
  if (HAL_SPI_Init(&hspi4) != HAL_OK)
  {
    Error_Handler();
  }

}

static void MX_TIM2_Init(void)
{

  TIM_MasterConfigTypeDef sMasterConfig = {0};
  TIM_OC_InitTypeDef sConfigOC = {0};

  htim2.Instance = TIM2;
  htim2.Init.Prescaler = 240;
  htim2.Init.CounterMode = TIM_COUNTERMODE_UP;
  htim2.Init.Period = 1000;
  htim2.Init.ClockDivision = TIM_CLOCKDIVISION_DIV1;
  htim2.Init.AutoReloadPreload = TIM_AUTORELOAD_PRELOAD_DISABLE;
  if (HAL_TIM_PWM_Init(&htim2) != HAL_OK)
  {
    Error_Handler();
  }
  sMasterConfig.MasterOutputTrigger = TIM_TRGO_RESET;
  sMasterConfig.MasterSlaveMode = TIM_MASTERSLAVEMODE_DISABLE;
  if (HAL_TIMEx_MasterConfigSynchronization(&htim2, &sMasterConfig) != HAL_OK)
  {
    Error_Handler();
  }
  sConfigOC.OCMode = TIM_OCMODE_PWM1;
  sConfigOC.Pulse = 900;
  sConfigOC.OCPolarity = TIM_OCPOLARITY_HIGH;
  sConfigOC.OCFastMode = TIM_OCFAST_DISABLE;
  if (HAL_TIM_PWM_ConfigChannel(&htim2, &sConfigOC, TIM_CHANNEL_4) != HAL_OK)
  {
    Error_Handler();
  }
  HAL_TIM_MspPostInit(&htim2);

}

static void MX_TIM4_Init(void)
{

  TIM_Encoder_InitTypeDef sConfig = {0};
  TIM_MasterConfigTypeDef sMasterConfig = {0};

  htim4.Instance = TIM4;
  htim4.Init.Prescaler = 0;
  htim4.Init.CounterMode = TIM_COUNTERMODE_UP;
  htim4.Init.Period = 65535;
  htim4.Init.ClockDivision = TIM_CLOCKDIVISION_DIV1;
  htim4.Init.AutoReloadPreload = TIM_AUTORELOAD_PRELOAD_DISABLE;
  sConfig.EncoderMode = TIM_ENCODERMODE_TI12;
  sConfig.IC1Polarity = TIM_ICPOLARITY_RISING;
  sConfig.IC1Selection = TIM_ICSELECTION_DIRECTTI;
  sConfig.IC1Prescaler = TIM_ICPSC_DIV2;
  sConfig.IC1Filter = 15;
  sConfig.IC2Polarity = TIM_ICPOLARITY_RISING;
  sConfig.IC2Selection = TIM_ICSELECTION_DIRECTTI;
  sConfig.IC2Prescaler = TIM_ICPSC_DIV2;
  sConfig.IC2Filter = 15;
  if (HAL_TIM_Encoder_Init(&htim4, &sConfig) != HAL_OK)
  {
    Error_Handler();
  }
  sMasterConfig.MasterOutputTrigger = TIM_TRGO_RESET;
  sMasterConfig.MasterSlaveMode = TIM_MASTERSLAVEMODE_DISABLE;
  if (HAL_TIMEx_MasterConfigSynchronization(&htim4, &sMasterConfig) != HAL_OK)
  {
    Error_Handler();
  }

}

static void MX_TIM5_Init(void)
{

  TIM_ClockConfigTypeDef sClockSourceConfig = {0};
  TIM_MasterConfigTypeDef sMasterConfig = {0};

  htim5.Instance = TIM5;
  htim5.Init.Prescaler = 1999;
  htim5.Init.CounterMode = TIM_COUNTERMODE_UP;
  htim5.Init.Period = 7199999;
  htim5.Init.ClockDivision = TIM_CLOCKDIVISION_DIV1;
  htim5.Init.AutoReloadPreload = TIM_AUTORELOAD_PRELOAD_DISABLE;
  if (HAL_TIM_Base_Init(&htim5) != HAL_OK)
  {
    Error_Handler();
  }
  sClockSourceConfig.ClockSource = TIM_CLOCKSOURCE_INTERNAL;
  if (HAL_TIM_ConfigClockSource(&htim5, &sClockSourceConfig) != HAL_OK)
  {
    Error_Handler();
  }
  sMasterConfig.MasterOutputTrigger = TIM_TRGO_RESET;
  sMasterConfig.MasterSlaveMode = TIM_MASTERSLAVEMODE_DISABLE;
  if (HAL_TIMEx_MasterConfigSynchronization(&htim5, &sMasterConfig) != HAL_OK)
  {
    Error_Handler();
  }

}

static void MX_TIM7_Init(void)
{

  TIM_MasterConfigTypeDef sMasterConfig = {0};

  htim7.Instance = TIM7;
  htim7.Init.Prescaler = 2;
  htim7.Init.CounterMode = TIM_COUNTERMODE_UP;
  htim7.Init.Period = 1811;
  htim7.Init.AutoReloadPreload = TIM_AUTORELOAD_PRELOAD_DISABLE;
  if (HAL_TIM_Base_Init(&htim7) != HAL_OK)
  {
    Error_Handler();
  }
  sMasterConfig.MasterOutputTrigger = TIM_TRGO_UPDATE;
  sMasterConfig.MasterSlaveMode = TIM_MASTERSLAVEMODE_DISABLE;
  if (HAL_TIMEx_MasterConfigSynchronization(&htim7, &sMasterConfig) != HAL_OK)
  {
    Error_Handler();
  }

}

static void MX_TIM13_Init(void)
{

  htim13.Instance = TIM13;
  htim13.Init.Prescaler = 60000;
  htim13.Init.CounterMode = TIM_COUNTERMODE_UP;
  htim13.Init.Period = 65535;
  htim13.Init.ClockDivision = TIM_CLOCKDIVISION_DIV4;
  htim13.Init.AutoReloadPreload = TIM_AUTORELOAD_PRELOAD_DISABLE;
  if (HAL_TIM_Base_Init(&htim13) != HAL_OK)
  {
    Error_Handler();
  }

}

static void MX_TIM14_Init(void)
{

  htim14.Instance = TIM14;
  htim14.Init.Prescaler = 1199;
  htim14.Init.CounterMode = TIM_COUNTERMODE_UP;
  htim14.Init.Period = 1999;
  htim14.Init.ClockDivision = TIM_CLOCKDIVISION_DIV1;
  htim14.Init.AutoReloadPreload = TIM_AUTORELOAD_PRELOAD_DISABLE;
  if (HAL_TIM_Base_Init(&htim14) != HAL_OK)
  {
    Error_Handler();
  }

}

static void MX_TIM15_Init(void)
{

  TIM_ClockConfigTypeDef sClockSourceConfig = {0};
  TIM_MasterConfigTypeDef sMasterConfig = {0};

  htim15.Instance = TIM15;
  htim15.Init.Prescaler = 240;
  htim15.Init.CounterMode = TIM_COUNTERMODE_UP;
  htim15.Init.Period = 10000;
  htim15.Init.ClockDivision = TIM_CLOCKDIVISION_DIV1;
  htim15.Init.RepetitionCounter = 0;
  htim15.Init.AutoReloadPreload = TIM_AUTORELOAD_PRELOAD_DISABLE;
  if (HAL_TIM_Base_Init(&htim15) != HAL_OK)
  {
    Error_Handler();
  }
  sClockSourceConfig.ClockSource = TIM_CLOCKSOURCE_INTERNAL;
  if (HAL_TIM_ConfigClockSource(&htim15, &sClockSourceConfig) != HAL_OK)
  {
    Error_Handler();
  }
  sMasterConfig.MasterOutputTrigger = TIM_TRGO_UPDATE;
  sMasterConfig.MasterSlaveMode = TIM_MASTERSLAVEMODE_DISABLE;
  if (HAL_TIMEx_MasterConfigSynchronization(&htim15, &sMasterConfig) != HAL_OK)
  {
    Error_Handler();
  }

}

static void MX_TIM16_Init(void)
{

  htim16.Instance = TIM16;
  htim16.Init.Prescaler = 120;
  htim16.Init.CounterMode = TIM_COUNTERMODE_UP;
  htim16.Init.Period = 65535;
  htim16.Init.ClockDivision = TIM_CLOCKDIVISION_DIV1;
  htim16.Init.RepetitionCounter = 0;
  htim16.Init.AutoReloadPreload = TIM_AUTORELOAD_PRELOAD_DISABLE;
  if (HAL_TIM_Base_Init(&htim16) != HAL_OK)
  {
    Error_Handler();
  }

}

static void MX_TIM17_Init(void)
{

  htim17.Instance = TIM17;
  htim17.Init.Prescaler = 1199;
  htim17.Init.CounterMode = TIM_COUNTERMODE_UP;
  htim17.Init.Period = 9999;
  htim17.Init.ClockDivision = TIM_CLOCKDIVISION_DIV1;
  htim17.Init.RepetitionCounter = 0;
  htim17.Init.AutoReloadPreload = TIM_AUTORELOAD_PRELOAD_DISABLE;
  if (HAL_TIM_Base_Init(&htim17) != HAL_OK)
  {
    Error_Handler();
  }

}

static void MX_DMA_Init(void)
{

  /* DMA controller clock enable */
  __HAL_RCC_DMA1_CLK_ENABLE();

  /* DMA interrupt init */
  /* DMA1_Stream0_IRQn interrupt configuration */
  HAL_NVIC_SetPriority(DMA1_Stream0_IRQn, 0, 0);
  HAL_NVIC_EnableIRQ(DMA1_Stream0_IRQn);
  /* DMA1_Stream2_IRQn interrupt configuration */
  HAL_NVIC_SetPriority(DMA1_Stream2_IRQn, 0, 0);
  HAL_NVIC_EnableIRQ(DMA1_Stream2_IRQn);
  /* DMA1_Stream3_IRQn interrupt configuration */
  HAL_NVIC_SetPriority(DMA1_Stream3_IRQn, 0, 0);
  HAL_NVIC_EnableIRQ(DMA1_Stream3_IRQn);
  /* DMA1_Stream4_IRQn interrupt configuration */
  HAL_NVIC_SetPriority(DMA1_Stream4_IRQn, 0, 0);
  HAL_NVIC_EnableIRQ(DMA1_Stream4_IRQn);

}

static void MX_GPIO_Init(void)
{
  GPIO_InitTypeDef GPIO_InitStruct = {0};

  /* GPIO Ports Clock Enable */
  __HAL_RCC_GPIOE_CLK_ENABLE();
  __HAL_RCC_GPIOH_CLK_ENABLE();
  __HAL_RCC_GPIOC_CLK_ENABLE();
  __HAL_RCC_GPIOA_CLK_ENABLE();
  __HAL_RCC_GPIOB_CLK_ENABLE();
  __HAL_RCC_GPIOD_CLK_ENABLE();

  /*Configure GPIO pin Output Level */
  HAL_GPIO_WritePin(GPIOE, SYSTEM_LED_Pin|LCDRESET_Pin, GPIO_PIN_RESET);

  /*Configure GPIO pin Output Level */
  HAL_GPIO_WritePin(TRIGGER_OUT_GPIO_Port, TRIGGER_OUT_Pin, GPIO_PIN_RESET);

  /*Configure GPIO pin Output Level */
  HAL_GPIO_WritePin(GPIOE, TOUCH_CS_Pin|FLASH_SS_Pin|LCDCS_Pin, GPIO_PIN_SET);

  /*Configure GPIO pin Output Level */
  HAL_GPIO_WritePin(GPIOB, FLAG_Pin|LD8_Pin|LD7_Pin, GPIO_PIN_RESET);

  /*Configure GPIO pin Output Level */
  HAL_GPIO_WritePin(LD1_GPIO_Port, LD1_Pin, GPIO_PIN_RESET);

  /*Configure GPIO pin Output Level */
  HAL_GPIO_WritePin(LCDDC_GPIO_Port, LCDDC_Pin, GPIO_PIN_RESET);

  /*Configure GPIO pin : SYSTEM_LED_Pin */
  GPIO_InitStruct.Pin = SYSTEM_LED_Pin;
  GPIO_InitStruct.Mode = GPIO_MODE_OUTPUT_PP;
  GPIO_InitStruct.Pull = GPIO_NOPULL;
  GPIO_InitStruct.Speed = GPIO_SPEED_FREQ_LOW;
  HAL_GPIO_Init(SYSTEM_LED_GPIO_Port, &GPIO_InitStruct);

  /*Configure GPIO pin : TRIGGER_IN_Pin */
  GPIO_InitStruct.Pin = TRIGGER_IN_Pin;
  GPIO_InitStruct.Mode = GPIO_MODE_IT_RISING_FALLING;
  GPIO_InitStruct.Pull = GPIO_PULLUP;
  HAL_GPIO_Init(TRIGGER_IN_GPIO_Port, &GPIO_InitStruct);

  /*Configure GPIO pin : GATE_Pin */
  GPIO_InitStruct.Pin = GATE_Pin;
  GPIO_InitStruct.Mode = GPIO_MODE_INPUT;
  GPIO_InitStruct.Pull = GPIO_NOPULL;
  HAL_GPIO_Init(GATE_GPIO_Port, &GPIO_InitStruct);

  /*Configure GPIO pin : TRIGGER_OUT_Pin */
  GPIO_InitStruct.Pin = TRIGGER_OUT_Pin;
  GPIO_InitStruct.Mode = GPIO_MODE_OUTPUT_PP;
  GPIO_InitStruct.Pull = GPIO_NOPULL;
  GPIO_InitStruct.Speed = GPIO_SPEED_FREQ_LOW;
  HAL_GPIO_Init(TRIGGER_OUT_GPIO_Port, &GPIO_InitStruct);

  /*Configure GPIO pins : SW1_Pin SW2_Pin */
  GPIO_InitStruct.Pin = SW1_Pin|SW2_Pin;
  GPIO_InitStruct.Mode = GPIO_MODE_INPUT;
  GPIO_InitStruct.Pull = GPIO_PULLUP;
  HAL_GPIO_Init(GPIOC, &GPIO_InitStruct);

  /*Configure GPIO pins : TOUCH_CS_Pin LCDRESET_Pin LCDCS_Pin */
  GPIO_InitStruct.Pin = TOUCH_CS_Pin|LCDRESET_Pin|LCDCS_Pin;
  GPIO_InitStruct.Mode = GPIO_MODE_OUTPUT_PP;
  GPIO_InitStruct.Pull = GPIO_PULLUP;
  GPIO_InitStruct.Speed = GPIO_SPEED_FREQ_VERY_HIGH;
  HAL_GPIO_Init(GPIOE, &GPIO_InitStruct);

  /*Configure GPIO pin : TOUCH_IRQ_Pin */
  GPIO_InitStruct.Pin = TOUCH_IRQ_Pin;
  GPIO_InitStruct.Mode = GPIO_MODE_IT_FALLING;
  GPIO_InitStruct.Pull = GPIO_PULLUP;
  HAL_GPIO_Init(TOUCH_IRQ_GPIO_Port, &GPIO_InitStruct);

  /*Configure GPIO pin : FLASH_SS_Pin */
  GPIO_InitStruct.Pin = FLASH_SS_Pin;
  GPIO_InitStruct.Mode = GPIO_MODE_OUTPUT_PP;
  GPIO_InitStruct.Pull = GPIO_PULLUP;
  GPIO_InitStruct.Speed = GPIO_SPEED_FREQ_HIGH;
  HAL_GPIO_Init(FLASH_SS_GPIO_Port, &GPIO_InitStruct);

  /*Configure GPIO pin : FLAG_Pin */
  GPIO_InitStruct.Pin = FLAG_Pin;
  GPIO_InitStruct.Mode = GPIO_MODE_OUTPUT_PP;
  GPIO_InitStruct.Pull = GPIO_NOPULL;
  GPIO_InitStruct.Speed = GPIO_SPEED_FREQ_VERY_HIGH;
  HAL_GPIO_Init(FLAG_GPIO_Port, &GPIO_InitStruct);

  /*Configure GPIO pin : LD1_Pin */
  GPIO_InitStruct.Pin = LD1_Pin;
  GPIO_InitStruct.Mode = GPIO_MODE_OUTPUT_PP;
  GPIO_InitStruct.Pull = GPIO_NOPULL;
  GPIO_InitStruct.Speed = GPIO_SPEED_FREQ_LOW;
  HAL_GPIO_Init(LD1_GPIO_Port, &GPIO_InitStruct);

  /*Configure GPIO pin : LCDDC_Pin */
  GPIO_InitStruct.Pin = LCDDC_Pin;
  GPIO_InitStruct.Mode = GPIO_MODE_OUTPUT_PP;
  GPIO_InitStruct.Pull = GPIO_PULLUP;
  GPIO_InitStruct.Speed = GPIO_SPEED_FREQ_VERY_HIGH;
  HAL_GPIO_Init(LCDDC_GPIO_Port, &GPIO_InitStruct);

  /*Configure GPIO pin : MICROSD_PRESENT_Pin */
  GPIO_InitStruct.Pin = MICROSD_PRESENT_Pin;
  GPIO_InitStruct.Mode = GPIO_MODE_INPUT;
  GPIO_InitStruct.Pull = GPIO_PULLUP;
  HAL_GPIO_Init(MICROSD_PRESENT_GPIO_Port, &GPIO_InitStruct);

  /*Configure GPIO pin : ENCODER_BTN_Pin */
  GPIO_InitStruct.Pin = ENCODER_BTN_Pin;
  GPIO_InitStruct.Mode = GPIO_MODE_IT_FALLING;
  GPIO_InitStruct.Pull = GPIO_PULLUP;
  HAL_GPIO_Init(ENCODER_BTN_GPIO_Port, &GPIO_InitStruct);

  /*Configure GPIO pins : LD8_Pin LD7_Pin */
  GPIO_InitStruct.Pin = LD8_Pin|LD7_Pin;
  GPIO_InitStruct.Mode = GPIO_MODE_OUTPUT_PP;
  GPIO_InitStruct.Pull = GPIO_NOPULL;
  GPIO_InitStruct.Speed = GPIO_SPEED_FREQ_LOW;
  HAL_GPIO_Init(GPIOB, &GPIO_InitStruct);

  /* EXTI interrupt init*/
  HAL_NVIC_SetPriority(EXTI2_IRQn, 0, 0);
  HAL_NVIC_EnableIRQ(EXTI2_IRQn);

  HAL_NVIC_SetPriority(EXTI9_5_IRQn, 0, 0);
  HAL_NVIC_EnableIRQ(EXTI9_5_IRQn);

}

/* MPU Configuration */

void MPU_Config(void)
{
  MPU_Region_InitTypeDef MPU_InitStruct = {0};

  /* Disables the MPU */
  HAL_MPU_Disable();
  /** Initializes and configures the Region and the memory to be protected
  */
  MPU_InitStruct.Enable = MPU_REGION_ENABLE;
  MPU_InitStruct.Number = MPU_REGION_NUMBER0;
  MPU_InitStruct.BaseAddress = 0x38000000;
  MPU_InitStruct.Size = MPU_REGION_SIZE_64KB;
  MPU_InitStruct.SubRegionDisable = 0x0;
  MPU_InitStruct.TypeExtField = MPU_TEX_LEVEL1;
  MPU_InitStruct.AccessPermission = MPU_REGION_FULL_ACCESS;
  MPU_InitStruct.DisableExec = MPU_INSTRUCTION_ACCESS_ENABLE;
  MPU_InitStruct.IsShareable = MPU_ACCESS_NOT_SHAREABLE;
  MPU_InitStruct.IsCacheable = MPU_ACCESS_NOT_CACHEABLE;
  MPU_InitStruct.IsBufferable = MPU_ACCESS_NOT_BUFFERABLE;

  HAL_MPU_ConfigRegion(&MPU_InitStruct);
  /* Enables the MPU */
  HAL_MPU_Enable(MPU_PRIVILEGED_DEFAULT);

}

void Error_Handler(void)
{
  __disable_irq();
  while (1)
  {
  }
}
